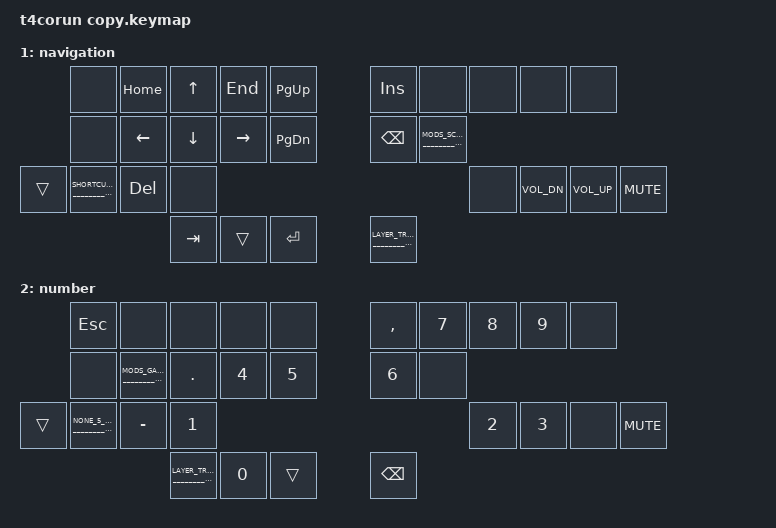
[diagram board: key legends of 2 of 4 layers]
#include <behaviors.dtsi>
#include <dt-bindings/zmk/keys.h>
#include <dt-bindings/zmk/bt.h>
#include <dt-bindings/zmk/outputs.h>

//-----------------------------------

// put the default base layers first
#define _QWERTY     0
#define _NAVIGATION 1
#define _NUMBER     2
#define _SYMBOL     3

// layer changes
#define NUM                  &mo _NUMBER
#define NAV                  &mo _NAVIGATION

//Behavior Configuration
#define TAPPING_TERM 200

//                           xxxxxxxxxx|xxxxxxxxxx|xxxxxxxxxx|xxxxxxxxxx|xxxxxxxxxx|xxxxxxxxxx
#define HRML(k1, k2, k3, k4) &mt LGUI k1   &mt LALT k2   &mt LCTRL k3  &mt LSHFT k4
#define HRMR(k1, k2, k3, k4) &mt RSHFT k1  &mt RCTRL k2  &mt RALT k3   &mt RGUI  k4

//#define HT(hold, tap)        &ht hold tap
#define KO_COMMA             &ht LPAR      COMMA
#define KO_DOT               &ht RPAR      DOT
#define KO_MINUS             &ht UNDER     MINUS


#define MACRO_BRC            &ht &brc_macro LBRC
#define MACRO_LGT            &ht &lgt_macro LT
#define MACRO_BKT            &ht &bkt_macro LBKT
#define MACRO_PAR            &ht &insert_braces LPAR RPAR LPAR


//                                                             xxxxxxxxxx|xxxxxxxxxx|xxxxxxxxxx|xxxxxxxxxx|xxxxxxxxxx|xxxxxxxxxx

#define __________                                             &trans
#define ____xx____                                             &none
#define _BASE_L4________________________                       &kp TAB    NUM        &kp LSHFT
#define _BASE_R4________________________                       &kp SPACE  NAV        &kp BSPC
#define _LAYER_TRANS____________________                       ____xx____ __________ ____xx____
#define _MODS_GACS_________________________________            &kp LGUI   &kp LALT   &kp LCTRL  &kp LSHFT
#define _MODS_SCAG_________________________________            &kp RSHFT  &kp RCTRL  &kp RALT   &kp RGUI
#define _SHORTCUTS_UCCPR______________________________________ &kp LC(Z)  &kp LC(X)  &kp LC(C)  &kp LC(V)  &kp LC(Y)
#define _NONE_5_______________________________________________ ____xx____ ____xx____ ____xx____ ____xx____ ____xx____



//-----------------------------------

&lt {
    flavor = "tap-preferred";
    tapping-term-ms = <TAPPING_TERM>; // this works because ZMK processes C before devicetree files
};

&mt {
    flavor = "tap-preferred";
    tapping-term-ms = <TAPPING_TERM>;
};

/ {
    behaviors {
        ht: hold_tap {
            compatible = "zmk,behavior-hold-tap";
            #binding-cells = <2>;
            flavor = "tap-preferred";
			tapping-term-ms = <TAPPING_TERM>;
			quick_tap_ms = <0>;
            bindings = <&kp>, <&kp>;
        };
    };

    macros {

		// macros
		ZMK_MACRO(insert_braces_par,
		    wait-ms = <0>;
		    tap-ms = <5>;
		    bindings = <
				&kp LPAR 
				&kp RPAR 
				&kp LEFT
			>;
		)

        brc_macro: brace_macro {
            compatible = "zmk,behavior-macro";
            #binding-cells = <0>;
            bindings = <
				&kp LBRC
				&kp RBRC
				&kp LEFT
			>;
        };

        lgt_macro: lessthan_greaterthan_macro {
            compatible = "zmk,behavior-macro";
            #binding-cells = <0>;
            bindings = <
				&kp LT
				&kp GT	
				&kp LEFT
			>;
        };

        bkt_macro: bracket_macro {
            compatible = "zmk,behavior-macro";
            #binding-cells = <0>;
            bindings = <
				&kp LBKT
				&kp RBKT
				&kp LEFT
			>;
        };

        par_macro: parenthesis_macro {
            compatible = "zmk,behavior-macro";
            #binding-cells = <0>;
            bindings = <
				&kp LPAR
				&kp RPAR
				&kp LEFT
			>;
        };

		insert_braces: insert_braces_macro {
            compatible = "zmk,behavior-macro-two-param";
            #binding-cells = <2>;
            bindings =
				<&macro_param_1to1>, 
				<&macro_press &kp MACRO_PLACEHOLDER>,
				<&macro_param_2to1>,
				<&macro_press &kp MACRO_PLACEHOLDER>,
				<&macro_press &kp LEFT>,
        		<&macro_pause_for_release>,
				<&macro_release &kp LEFT>,
				<&macro_param_2to1>,
				<&macro_release &kp MACRO_PLACEHOLDER>,
				<&macro_param_1to1>, 
				<&macro_release &kp MACRO_PLACEHOLDER>;
		};
    };

    conditional_layers {
        compatible = "zmk,conditional-layers";
        tri_layer {
            if-layers = <_NUMBER _NAVIGATION>;
            then-layer = <_SYMBOL>;
        };
    };

    keymap {
        compatible = "zmk,keymap";

// 				xxxxxxxxxx|xxxxxxxxxx|xxxxxxxxxx|xxxxxxxxxx|xxxxxxxxxx|xxxxxxxxxx           xxxxxxxxxx|xxxxxxxxxx|xxxxxxxxxx|xxxxxxxxxx|xxxxxxxxxx|xxxxxxxxxx

		qwerty {
			bindings = <
                           &kp Q      &kp W      &kp E      &kp R      &kp T                &kp Y      &kp U      &kp I      &kp O      &kp P
                           HRML(A,    S,         D,         F)         &kp G                &kp H      HRMR(J,    K,         L,         SQT)
	            &kp Z      &kp Z      &kp X      &kp C      &kp V      &kp B                &kp N      &kp M      KO_COMMA   KO_DOT     KO_MINUS   &kp APOSTROPHE
				                                 _BASE_L4________________________           _BASE_R4________________________
			>;
		};

		navigation {
			bindings = <
                           ____xx____ &kp HOME   &kp UP     &kp END    &kp PG_UP            &kp INS    ____xx____ ____xx____ ____xx____   ____xx____
                           ____xx____ &kp LEFT   &kp DOWN   &kp RIGHT  &kp PG_DN            &kp BSPC   _MODS_SCAG_________________________________
	            __________ _SHORTCUTS_UCCPR______________________________________           &kp DEL    ____xx____ ____xx____ &kp C_VOL_DN &kp C_VOL_UP &kp C_MUTE
				                                 &kp TAB    __________ &kp ENTER            _LAYER_TRANS____________________
			>;
		};

		number {
			bindings = <
                           &kp ESC    ____xx____ ____xx____ ____xx____ ____xx____           &kp COMMA  &kp N7     &kp N8     &kp N9     ____xx____
                           ____xx____ _MODS_GACS_________________________________           &kp DOT    &kp N4     &kp N5     &kp N6     ____xx____
	            __________ _NONE_5_______________________________________________           &kp MINUS  &kp N1     &kp N2     &kp N3     ____xx____ &kp C_MUTE
				                                 _LAYER_TRANS____________________           &kp N0     __________ &kp BSPC
			>;
		};

		symbol {
			bindings = <
                           &kp CARET  &kp AMPS   &kp AT     &kp DLLR   &kp GRAVE            &kp TILDE  &kp POUND  &kp ASTRK  &kp PLUS   ____xx____
                           &kp PRCNT  MACRO_BRC  &kp RBRC   ____xx____ &kp SEMI             &kp COLON  &kp EQUAL  MACRO_BKT  &kp RBKT   ____xx____
	            __________ ____xx____ MACRO_LGT  &kp GT     ____xx____ &kp EXCL             &kp QMARK  ____xx____ MACRO_PAR  &kp RPAR   ____xx____ &kp C_MUTE
				                                 _LAYER_TRANS____________________           _LAYER_TRANS____________________
			>;
		};
    };
};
